# DSS0_COMMON1 register map
Vendor: Texas Instruments
Peripheral module from a debugger description file (folder am65x).
Registers are 32-bit, access not given, reset 0x0 unless marked. A register's access mark holds for its fields unless they carry their own. Offsets are as the file gives them; lines under a group give offsets from that group; [hi:lo] are bit positions; {n}, {i} and the like mark numbered series; 'fields as' and 'values as' point back to an identical list; <NAME> marks a mode.

## DSS0_COMMON1
0x00 DSS0_COMMON1_DISPC_IRQ_EOI access per field — End Of Interrupt number The EOI register is used to re-trigger the pulse interrupt signal to ensure that any nested interrupt events are serviced. The software interrupt handler must write to the EOI register at the end of the current interrupt processing routine, so that new events can re-trigger the pulse interrupt signal again. For level interrupt signals the EOI register is not functional and must not be used.
  [0] EOI wo — Software End Of Interrupt [EOI] control if pulse interrupts are used. Write 1 to acknowledge interrupt 0h = Write-0 : No action 1h = Write-1 : End-of-Interrupt
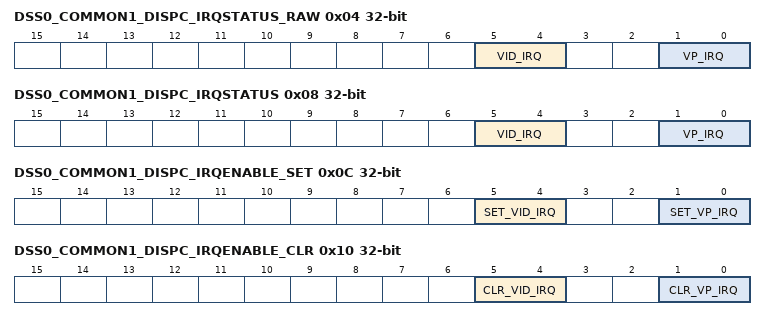
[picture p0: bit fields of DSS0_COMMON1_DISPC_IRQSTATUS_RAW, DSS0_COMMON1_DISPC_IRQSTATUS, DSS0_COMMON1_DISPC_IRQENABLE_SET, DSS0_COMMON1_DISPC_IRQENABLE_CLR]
0x04 DSS0_COMMON1_DISPC_IRQSTATUS_RAW — RAW Interrupt status. Raw status is set even if interrupt is not enabled. Write 1 to set the RAW status
  [5:4] VID_IRQ — VID IRQ STATUS. Register indicates the VIDEO pipeline[s] interrupt events. Bit [5] is for VIDL1 pipeline. Bit [4] is for VID pipeline. 0h = Write-0 : No action, Read-0 : No event pending 1h = Write-1 : Set event, Read-1 : IRQ event pending (access RW1S)
  [1:0] VP_IRQ — VP IRQ STATUS. Register indicates the Video Port[s] interrupt events. Bit [1] is for VP2. Bit [0] is for VP1. 0h = Write-0 : No action, Read-0 : No event pending 1h = Write-1 : Set event, Read-1 : IRQ event pending (access RW1S)
0x08 DSS0_COMMON1_DISPC_IRQSTATUS — Interrupt status. Enabled status, isn't set unless event is enabled. Write 1 to clear the status after interrupt has been serviced. RAW status also gets cleared, i.e. even if not enabled
  [5:4] VID_IRQ — VID IRQ STATUS. Register indicates the VIDEO pipeline[s] interrupt events. Bit [5] is for VIDL1 pipeline. Bit [4] is for VID pipeline. 0h = Write-0 : No action, Read-0 : No event pending 1h = Write-1 : Clear pending event, if any, Read-1 : IRQ event pending (access RW1C)
  [1:0] VP_IRQ — VP IRQ STATUS. Register indicates the Video Port[s] interrupt events. Bit [1] is for VP2. Bit [0] is for VP1. 0h = Write-0 : No action, Read-0 : No event pending 1h = Write-1 : Clear pending event, if any, Read-1 : IRQ event pending (access RW1C)
0x0C DSS0_COMMON1_DISPC_IRQENABLE_SET — SET Interrupt enable. Write 1 to set interrupt enable. Readout equal to corresponding _CLR register
  [5:4] SET_VID_IRQ — VID IRQ Bit [5] is for VIDL1 pipeline. Bit [4] is for VID pipeline. 0h = Write-0 : No action, Read-0 : Interrupt Disabled 1h = Write-1 : Enable interrupt, Read-1 : Interrupt Enabled (access RW1S)
  [1:0] SET_VP_IRQ — VP IRQ Bit [1] is for VP2. Bit [0] is for VP1. 0h = Write-0 : No action, Read-0 : Interrupt Disabled 1h = Write-1 : Enable interrupt, Read-1 : Interrupt Enabled (access RW1S)
0x10 DSS0_COMMON1_DISPC_IRQENABLE_CLR — CLR Interrupt enable. Write 1 to clear interrupt enable
  [5:4] CLR_VID_IRQ — VID IRQ Bit [5] is for VIDL1 pipeline. Bit [4] is for VID pipeline. 0h = Write-0 : No action, Read-0 : Interrupt Disabled 1h = Write-1 : Clear interrupt, Read-1 : Interrupt Enabled (access RW1C)
  [1:0] CLR_VP_IRQ — VP IRQ Bit [1] is for VP2. Bit [0] is for VP1. 0h = Write-0 : No action, Read-0 : Interrupt Disabled 1h = Write-1 : Clear interrupt, Read-1 : Interrupt Enabled (access RW1C)
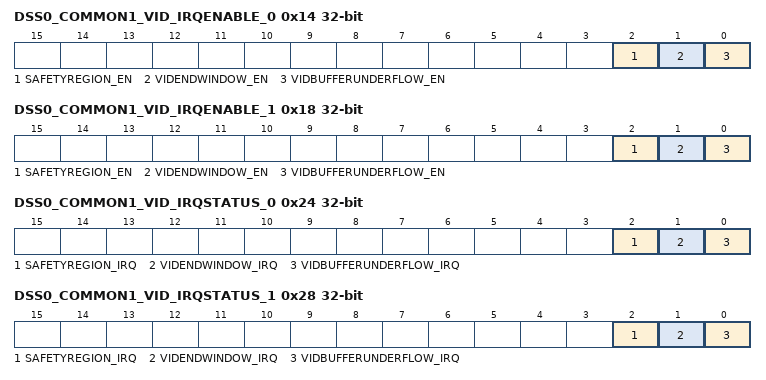
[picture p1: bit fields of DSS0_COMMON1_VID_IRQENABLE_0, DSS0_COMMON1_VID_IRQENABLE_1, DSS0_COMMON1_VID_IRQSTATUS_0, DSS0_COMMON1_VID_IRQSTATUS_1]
0x14 DSS0_COMMON1_VID_IRQENABLE_0 access per field — This register allows to mask/unmask the VID_0 internal sources of interrupt, on an event-by-event basis
  [2] SAFETYREGION_EN rw — Safety Feature IRQ. This is raised when FrameFreeze is detected or data mismatch occurs within the safety region 0h = Event is masked 1h = Event generates an interrupt when it occurs
  [1] VIDENDWINDOW_EN rw — Video End Window. This is raised by the DMA engine when the full video data has been sent to the pipeline 0h = Event is masked 1h = Event generates an interrupt when it occurs
  [0] VIDBUFFERUNDERFLOW_EN rw — Video DMA Buffer Underflow. This is raised when the DMA buffer does not have the data requested by the Video pipeline 0h = Event is masked 1h = Event generates an interrupt when it occurs
0x18 DSS0_COMMON1_VID_IRQENABLE_1 access per field — This register allows to mask/unmask the VIDL_0 internal sources of interrupt, on an event-by-event basis
  fields as DSS0_COMMON1_VID_IRQENABLE_0
0x24 DSS0_COMMON1_VID_IRQSTATUS_0 — This register groups all the status of the VID_0 internal events that generate an interrupt. Write 1 to a clear a bit field
  [2] SAFETYREGION_IRQ — Safety Feature IRQ. This is raised when FrameFreeze is detected or data mismatch occurs within the safety region 0h = Write: Status is unchanged, Read: Event is not pending 1h = Write: Status is reset, Read: Event is Pending (access RW1C)
  [1] VIDENDWINDOW_IRQ — Video End Window. This is raised by the DMA engine when the full video data has been sent to the pipeline 0h = Write: Status is unchanged, Read: Event is not pending 1h = Write: Status is reset, Read: Event is Pending (access RW1C)
  [0] VIDBUFFERUNDERFLOW_IRQ — Video DMA Buffer Underflow. This is raised when the DMA buffer does not have the data requested by the Video pipeline 0h = Write: Status is unchanged, Read: Event is not pending 1h = Write: Status is reset, Read: Event is Pending (access RW1C)
0x28 DSS0_COMMON1_VID_IRQSTATUS_1 — This register groups all the status of the VID_0 internal events that generate an interrupt. Write 1 to a clear a bit field
  fields as DSS0_COMMON1_VID_IRQSTATUS_0
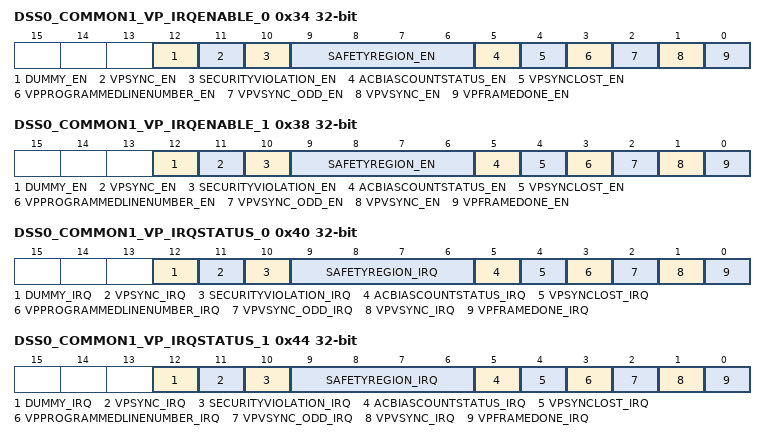
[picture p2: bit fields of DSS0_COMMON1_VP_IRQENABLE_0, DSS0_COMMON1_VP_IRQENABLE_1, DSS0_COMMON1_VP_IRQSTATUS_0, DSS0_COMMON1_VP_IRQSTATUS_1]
0x34 DSS0_COMMON1_VP_IRQENABLE_0 access per field — This register allows to mask/unmask the VP_0 internal sources of interrupt, on an event-by-event basis
  [12] DUMMY_EN rw — Dummy IRQ for future use 0h = Event is masked 1h = Event generates an interrupt when it occurs
  [11] VPSYNC_EN rw — Go bit clear event 0h = Event is masked 1h = Event generates an interrupt when it occurs
  [10] SECURITYVIOLATION_EN rw — Security Violation interrupt for OVR/VP. Non-secure OVR/VP connected to secure VID 0h = Event is masked 1h = Event generates an interrupt when it occurs
  [9:6] SAFETYREGION_EN rw — Safety Feature IRQ. This is raised when FrameFreeze is detected or data mismatch occurs within the safety region. Bit [9] is for safety region 3. Bit [8] is for safety region 2. Bit [7] is for safety region 1. Bit [6] is for safety region 0. 0h = Event is masked 1h = Event generates an interrupt when it occurs
  [5] ACBIASCOUNTSTATUS_EN rw — AC BIAS transition counter has decremented to zero 0h = Event is masked 1h = Event generates an interrupt when it occurs
  [4] VPSYNCLOST_EN rw — Synchronization Lost for Video Port 0h = Event is masked 1h = Event generates an interrupt when it occurs
  [3] VPPROGRAMMEDLINENUMBER_EN rw — Programmed Line Number. It indicates that the scan of the display has reached the programmed user line number 0h = Event is masked 1h = Event generates an interrupt when it occurs
  [2] VPVSYNC_ODD_EN rw — VSYNC for odd field from interlace mode only 0h = Event is masked 1h = Event generates an interrupt when it occurs
  [1] VPVSYNC_EN rw — Vertical Synchronization for VP 0h = Event is masked 1h = Event generates an interrupt when it occurs
  [0] VPFRAMEDONE_EN rw — Frame Done for Video Port. VP output has been disabled by user. All the data have been sent 0h = Event is masked 1h = Event generates an interrupt when it occurs
0x38 DSS0_COMMON1_VP_IRQENABLE_1 access per field — This register allows to mask/unmask the VP_1 internal sources of interrupt, on an event-by-event basis
  fields as DSS0_COMMON1_VP_IRQENABLE_0
0x40 DSS0_COMMON1_VP_IRQSTATUS_0 — This register groups all the status of the VP_0 internal events that generate an interrupt. Write 1 to a given bit resets this bit
  [12] DUMMY_IRQ — Dummy IRQ for future use 0h = Write: Status is unchanged, Read: Event is not pending 1h = Write: Status is reset, Read: Event is Pending (access RW1C)
  [11] VPSYNC_IRQ — Go bit clear event 0h = Write: Status is unchanged, Read: Event is not pending 1h = Write: Status is reset, Read: Event is Pending (access RW1C)
  [10] SECURITYVIOLATION_IRQ — Security Violation IRQ. Non-secure OVR/VP connected to secure VID 0h = Write: Status is unchanged, Read: Event is not pending 1h = Write: Status is reset, Read: Event is Pending (access RW1C)
  [9:6] SAFETYREGION_IRQ — Safety Feature IRQ. This is raised when FrameFreeze is detected or data mismatch occurs within the safety region. Bit [9] is for safety region 3. Bit [8] is for safety region 2. Bit [7] is for safety region 1. Bit [6] is for safety region 0. 0h = Write: Status is unchanged, Read: Event is not pending 1h = Write: Status is reset, Read: Event is Pending (access RW1C)
  [5] ACBIASCOUNTSTATUS_IRQ — AC BIAS transition counter has decremented to zero 0h = Write: Status is unchanged, Read: Event is not pending 1h = Write: Status is reset, Read: Event is Pending (access RW1C)
  [4] VPSYNCLOST_IRQ — Synchronization Lost on VP output. The required data are not output at the correct time due to too short blanking periods or stall of at least one pipelines associated with VP output 0h = Write: Status is unchanged, Read: Event is not pending 1h = Write: Status is reset, Read: Event is Pending (access RW1C)
  [3] VPPROGRAMMEDLINENUMBER_IRQ — Programmed Line Number. It indicates that the scan of the display has reached the programmed user line number 0h = Write: Status is unchanged, Read: Event is not pending 1h = Write: Status is reset, Read: Event is Pending (access RW1C)
  [2] VPVSYNC_ODD_IRQ — VSYNC for odd field. For interlace mode only 0h = Write: Status is unchanged, Read: Event is not pending 1h = Write: Status is reset, Read: Event is Pending (access RW1C)
  [1] VPVSYNC_IRQ — Vertical Synchronization for VP output. It is used as VSYNC_EVEN in case of interlace mode 0h = Write: Status is unchanged, Read: Event is not pending 1h = Write: Status is reset, Read: Event is Pending (access RW1C)
  [0] VPFRAMEDONE_IRQ — Frame Done for VP. VP output has been disabled by user All the data have been sent 0h = Write: Status is unchanged, Read: Event is not pending 1h = Write: Status is reset, Read: Event is Pending (access RW1C)
0x44 DSS0_COMMON1_VP_IRQSTATUS_1 — This register groups all the status of the VP_1 internal events that generate an interrupt. Write 1 to a given bit resets this bit
  fields as DSS0_COMMON1_VP_IRQSTATUS_0
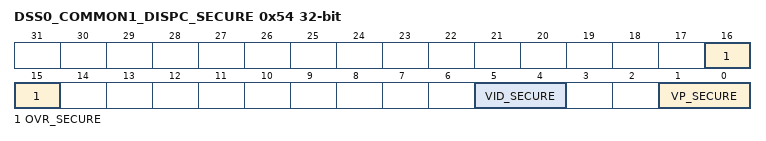
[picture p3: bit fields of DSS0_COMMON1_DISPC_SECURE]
0x54 DSS0_COMMON1_DISPC_SECURE access per field — Security bit settings for different DISPC sub-modules
  [16:15] OVR_SECURE rw — Secure bit for OVR Bit [16] is for OVR2. Bit [15] is for OVR1. 0h = Secure bit is reset 1h = Secure bit is set
  [5:4] VID_SECURE rw — Secure bit for VID Bit [5] is for VIDL1 pipeline. Bit [4] is for VID pipeline. 0h = Secure bit is reset 1h = Secure bit is set
  [1:0] VP_SECURE rw — Secure bit for VP Bit [1] is for VP2. Bit [0] is for VP1. 0h = Secure bit is reset 1h = Secure bit is set
